AUTOSAR XML (schema 00050)
package /Components
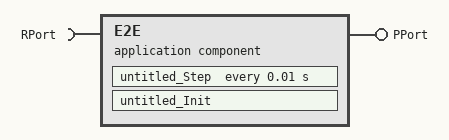
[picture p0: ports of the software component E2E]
  application sw component type E2E
    require port RPort: nonqueued-receiver-com-spec{data-element=In2, uses-end-to-end-protection=true, init-value=0}, required-interface=RPort
    provide port PPort: nonqueued-sender-com-spec{data-element=Out2, uses-end-to-end-protection=true, init-value=0}, provided-interface=PPort
    behavior untitled_IB: handle-termination-and-restart=NO-SUPPORT
      timing event Event_untitled_Step: start-on-event=untitled_Step, period=0.01
      runnable untitled_Init
      runnable untitled_Step
        data-receive-point-by-arguments:
          access IN_RPort_In2: accessed-variable=RPort.In2
        data-send-points:
          access OUT_PPort_Out2: accessed-variable=PPort.Out2
